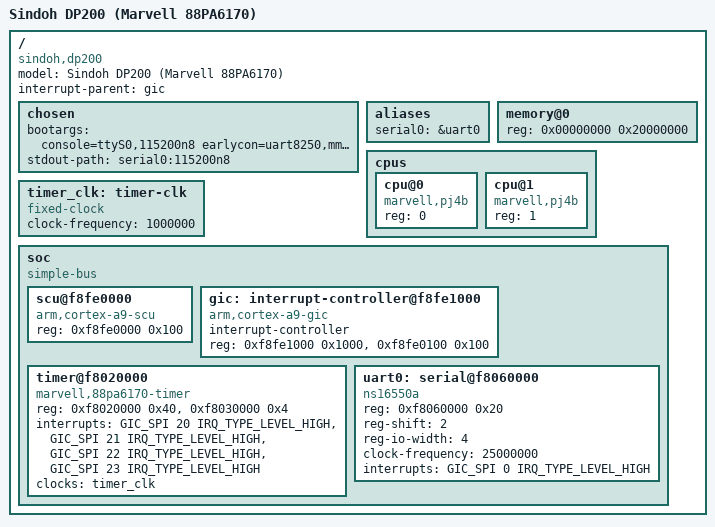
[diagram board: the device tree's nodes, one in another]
// SPDX-License-Identifier: GPL-2.0
/*
 * DRAFT, not built or booted yet. Milestone 1 of the mainline route
 * (docs/no_gpl_plan.md): one CPU, GIC, SoC timer, UART0, initramfs.
 *
 * Every address and IRQ here comes from the vendor kernel image
 * (tools/kernel_re/, docs/kernel/vendor_hwtables.txt) or the hardware
 * snapshot. The vendor kernel numbers IRQs as GIC IDs (gic_init with
 * irq_start 29 gives an offset of 0), so GIC_SPI n = vendor IRQ n - 32.
 * Open points are marked TODO and listed in no_gpl_plan.md, "Facts still
 * missing".
 *
 * Boot: zImage + this DTB appended (CONFIG_ARM_APPENDED_DTB,
 * CONFIG_ARM_ATAG_DTB_COMPAT), wrapped with mkimage for U-Boot 2011.09
 * "bootm" (no bootz, no fdt command in this U-Boot).
 */
/dts-v1/;

#include <dt-bindings/interrupt-controller/arm-gic.h>
#include <dt-bindings/interrupt-controller/irq.h>

/ {
	model = "Sindoh DP200 (Marvell 88PA6170)";
	compatible = "sindoh,dp200", "marvell,88pa6170";
	#address-cells = <1>;
	#size-cells = <1>;
	interrupt-parent = <&gic>;

	chosen {
		/* earlycon needs no driver beyond 8250: the first sign of life */
		bootargs = "console=ttyS0,115200n8 earlycon=uart8250,mmio32,0xf8060000 maxcpus=1 rdinit=/init";
		stdout-path = "serial0:115200n8";
	};

	aliases {
		serial0 = &uart0;
	};

	memory@0 {
		device_type = "memory";
		reg = <0x00000000 0x20000000>;	/* 512 MB, ATAGS agree */
	};

	cpus {
		#address-cells = <1>;
		#size-cells = <0>;

		/* PJ4B-MP, MIDR 0x562f5841: matches proc-v7.S __v7_pj4b_setup */
		cpu@0 {
			device_type = "cpu";
			compatible = "marvell,pj4b";
			reg = <0>;
		};

		/*
		 * Second CPU for later (milestone 1 runs maxcpus=1). Vendor
		 * boot_secondary: write the physical address of
		 * secondary_startup to 0xfa000000, then send an SGI.
		 */
		cpu@1 {
			device_type = "cpu";
			compatible = "marvell,pj4b";
			reg = <1>;
		};
	};

	/* Timer input after the prescaler at 0xf8030000 (busfreq / 1 MHz) */
	timer_clk: timer-clk {
		compatible = "fixed-clock";
		#clock-cells = <0>;
		clock-frequency = <1000000>;
	};

	soc {
		compatible = "simple-bus";
		#address-cells = <1>;
		#size-cells = <1>;
		ranges;

		/* A9-style private region: SCU +0, GIC CPU +0x100, GIC dist +0x1000 */
		scu@f8fe0000 {
			compatible = "arm,cortex-a9-scu";
			reg = <0xf8fe0000 0x100>;
		};

		gic: interrupt-controller@f8fe1000 {
			compatible = "arm,cortex-a9-gic";
			#interrupt-cells = <3>;
			interrupt-controller;
			reg = <0xf8fe1000 0x1000>,
			      <0xf8fe0100 0x100>;
		};

		/*
		 * TODO: if a TWD answers at 0xf8fe0600 (unknown, see the plan),
		 * "arm,cortex-a9-twd-timer" would replace the new driver below
		 * for the clockevent.
		 */

		/*
		 * SoC timer block, needs a new ~150-line driver.
		 * Per timer n (n = 0..3), base + 0x10*n: +0x04 load,
		 * +0x08 control (bit0 enable, bit1 auto-reload), +0x0c count.
		 * +0x10 IRQ status (bit n), +0x20 IRQ clear (write bit n).
		 * Vendor: timer1 = clockevent (IRQ 53), timer2 = free-running
		 * clocksource loaded with 0xffffffff (TODO: count direction).
		 */
		timer@f8020000 {
			compatible = "marvell,88pa6170-timer";
			reg = <0xf8020000 0x40>, <0xf8030000 0x4>;
			interrupts = <GIC_SPI 20 IRQ_TYPE_LEVEL_HIGH>,
				     <GIC_SPI 21 IRQ_TYPE_LEVEL_HIGH>,
				     <GIC_SPI 22 IRQ_TYPE_LEVEL_HIGH>,
				     <GIC_SPI 23 IRQ_TYPE_LEVEL_HIGH>;
			clocks = <&timer_clk>;
		};

		/* serial0_platform_data: uartclk 25 MHz, regshift 2, UPIO_MEM32 */
		uart0: serial@f8060000 {
			compatible = "ns16550a";
			reg = <0xf8060000 0x20>;
			reg-shift = <2>;
			reg-io-width = <4>;
			clock-frequency = <25000000>;
			interrupts = <GIC_SPI 0 IRQ_TYPE_LEVEL_HIGH>;
		};
	};
};
